# StarFive VisionFive 2 v1.2A register map
File version: 0.1
Registers are 32-bit, read-write, reset 0x0 unless marked. A register's access mark holds for its fields unless they carry their own. Offsets are from the block's base; [hi:lo] are bit positions; 'fields as' and 'values as' point back to an identical list.

## qspi — From cdns,qspi-nor, peripheral generator
Base 0x13010000
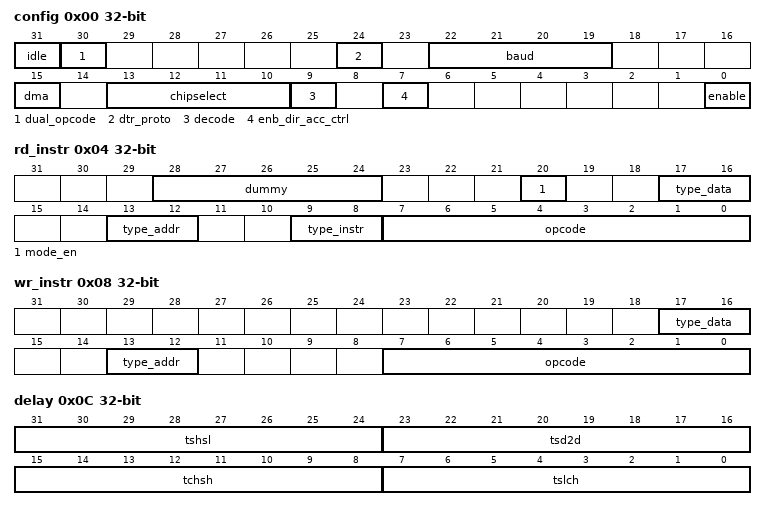
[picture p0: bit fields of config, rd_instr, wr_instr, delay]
0x00 config — Cadence QSPI Configuration
  [31] idle — Set Idle
  [30] dual_opcode — Enable Dual Opcode Mode
  [24] dtr_proto — Enable DTR Protocol
  [22:19] baud — Set the QSPI BAUD rate divisor
  [15] dma — Enable Direct Memory Access
  [13:10] chipselect — Chip select - CS0: 0b1110, CS1: 0b1101, CS2: 0b1011, CS3: 0b0111
  [9] decode — Enable the QSPI decoder
  [7] enb_dir_acc_ctrl — Enable direct access controller
  [0] enable — Enable the QSPI controller
0x04 rd_instr — Cadence QSPI Read Instruction
  [28:24] dummy — Send dummy signal to stall the device
  [20] mode_en — Mode
  [17:16] type_data
  [13:12] type_addr — Type of Address
  [9:8] type_instr — Type of Instruction
  [7:0] opcode — Instruction Opcode
0x08 wr_instr — Cadence QSPI Write Instruction
  [17:16] type_data
  [13:12] type_addr — Type of Address
  [7:0] opcode — Instruction Opcode
0x0C delay — Cadence QSPI Delay
  [31:24] tshsl — TSHSL Delay Value
  [23:16] tsd2d — TSD2D Delay Value
  [15:8] tchsh — TCHSH Delay Value
  [7:0] tslch — TSLCH Delay Value
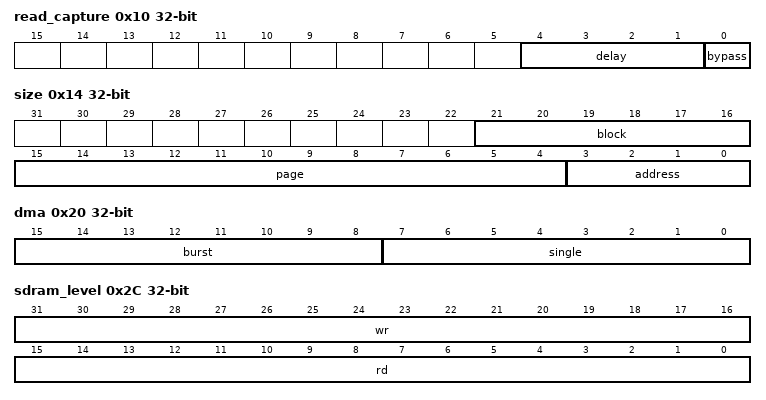
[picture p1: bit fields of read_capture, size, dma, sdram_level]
0x10 read_capture — Cadence QSPI Read Capture
  [4:1] delay — Read Capture Delay Value
  [0] bypass — Bypass the Read Capture
0x14 size — Cadence QSPI Size Configuration
  [21:16] block — Block Size in Bytes
  [15:4] page — Page Size in Bytes
  [3:0] address — Address Size in Bytes
0x18 sram_partition — Cadence QSPI SRAM Partition Size
  [31:0] size — Partition size in bytes
0x1C indirect_trigger — Cadence QSPI Indirect Trigger Address
  [31:0] address
0x20 dma — Cadence QSPI Direct Memory Access
  [15:8] burst, [7:0] single
0x24 remap — Cadence QSPI Remap Address
  [31:0] address
0x28 mode_bit — Cadence QSPI Mode Bit(s)
  [31:0] mode
0x2C sdram_level — Cadence QSPI SDRAM Level
  [31:16] wr ro — SDRAM Write Level
  [15:0] rd ro — SDRAM Read Level
0x38 wr_completion_ctrl — Cadence QSPI Write Completion Control
  [14] disable_auto_poll — SPI NAND flashes require the address of the status register to be passed in the Read SR command. Also, some SPI NOR flashes like the Cypress Semper flash expect a 4-byte dummy address in the Read SR command in DTR mode. But this controller does not support address phase in the Read SR command when doing auto-HW polling. So, disable write completion polling on the controller's side. spi-nand and spi-nor will take care of polling the status register.
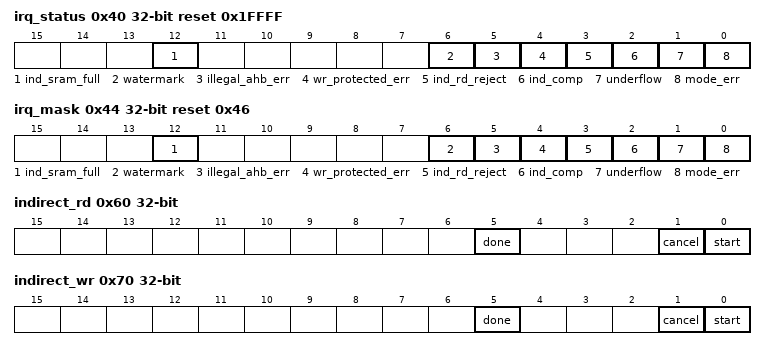
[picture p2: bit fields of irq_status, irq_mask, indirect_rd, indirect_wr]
0x40 irq_status reset 0x1FFFF — Cadence QSPI IRQ Status
  [12] ind_sram_full — Indirect SRAM full interrupt
  [6] watermark — Watermark interrupt
  [5] illegal_ahb_err — Illegal AHB clock error interrupt
  [4] wr_protected_err — Write protected error interrupt
  [3] ind_rd_reject — Indirect read rejection interrupt
  [2] ind_comp — Indirect computation interrupt
  [1] underflow — Buffer underflow interrupt
  [0] mode_err — Mode error interrupt
0x44 irq_mask reset 0x46 — Cadence QSPI IRQ Mask
  fields as irq_status
0x60 indirect_rd — Cadence QSPI Indirect Read
  [5] done — Indirect read done
  [1] cancel — Cancel indirect read
  [0] start — Start indirect read
0x64 indirect_rd_watermark — Cadence QSPI Indirect Read Watermark
0x68 indirect_rd_start_addr — Cadence QSPI Indirect Read Start Address
  [31:0] address
0x6C indirect_rd_bytes — Cadence QSPI Indirect Read Bytes
0x70 indirect_wr — Cadence QSPI Indirect Write
  [5] done — Indirect write done
  [1] cancel — Cancel indirect write
  [0] start — Start indirect write
0x74 indirect_wr_watermark — Cadence QSPI Indirect Write Watermark
0x78 indirect_wr_start_addr — Cadence QSPI Indirect Write Start Address
  [31:0] address
0x7C indirect_wr_bytes — Cadence QSPI Indirect Write Bytes
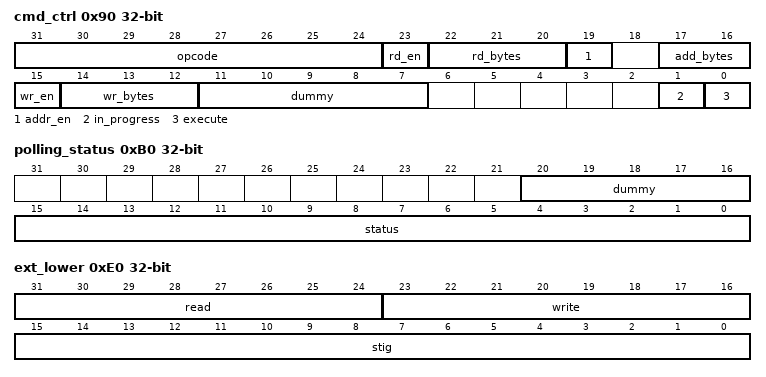
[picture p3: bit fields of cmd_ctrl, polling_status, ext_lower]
0x90 cmd_ctrl — Cadence QSPI Command Control
  [31:24] opcode — Command opcode
  [23] rd_en — Read enable
  [22:20] rd_bytes — Read bytes
  [19] addr_en — Address enable
  [17:16] add_bytes — Add command bytes
  [15] wr_en — Write enable
  [14:12] wr_bytes — Write bytes
  [11:7] dummy — Dummy command
  [1] in_progress — Command in progress
  [0] execute — Execute-in-Place (XIP)
0x94 cmd_address — Cadence QSPI Command Address
0xA0 cmd_read_at_lower — Cadence QSPI Command Read at Lower
  [31:0] read_at_lower
0xA4 cmd_read_at_upper — Cadence QSPI Command Read at Upper
  [31:0] read_at_upper
0xA8 cmd_write_at_lower — Cadence QSPI Command Write at Lower
  [31:0] write_at_lower
0xAC cmd_write_at_upper — Cadence QSPI Command Write at Upper
  [31:0] write_at_upper
0xB0 polling_status — Cadence QSPI Polling Status
  [20:16] dummy, [15:0] status
0xE0 ext_lower — Cadence QSPI Extension Lower
  [31:24] read, [23:16] write, [15:0] stig
